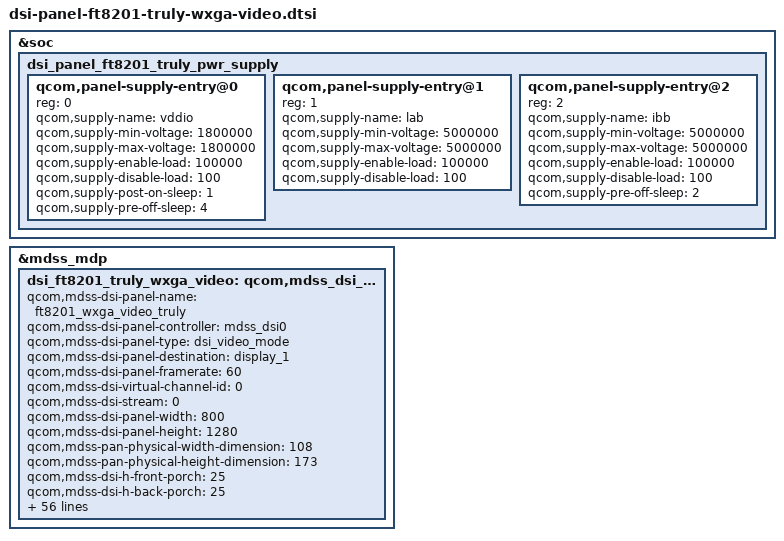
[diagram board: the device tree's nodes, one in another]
/* Copyright (c) 2013, The Linux Foundation. All rights reserved.
 *
 * This program is free software; you can redistribute it and/or modify
 * it under the terms of the GNU General Public License version 2 and
 * only version 2 as published by the Free Software Foundation.
 *
 * This program is distributed in the hope that it will be useful,
 * but WITHOUT ANY WARRANTY; without even the implied warranty of
 * MERCHANTABILITY or FITNESS FOR A PARTICULAR PURPOSE.  See the
 * GNU General Public License for more details.
 */

/*---------------------------------------------------------------------------
 * This file is autogenerated file using gcdb parser. Please do not edit it.
 * Update input XML file to add a new entry or update variable in this file
 * VERSION = "1.0"
 *---------------------------------------------------------------------------*/
&soc {
	dsi_panel_ft8201_truly_pwr_supply: dsi_panel_ft8201_truly_pwr_supply {
		#address-cells = <1>;
		#size-cells = <0>;

		qcom,panel-supply-entry@0 {
			reg = <0>;
			qcom,supply-name = "vddio";
			qcom,supply-min-voltage = <1800000>;
			qcom,supply-max-voltage = <1800000>;
			qcom,supply-enable-load = <100000>;
			qcom,supply-disable-load = <100>;
			qcom,supply-post-on-sleep = <1>;
			qcom,supply-pre-off-sleep = <4>;
		};

		qcom,panel-supply-entry@1 {
			reg = <1>;
			qcom,supply-name = "lab";
			qcom,supply-min-voltage = <5000000>;
			qcom,supply-max-voltage = <5000000>;
			qcom,supply-enable-load = <100000>;
			qcom,supply-disable-load = <100>;
			//qcom,supply-post-off-sleep = <1>;
		};

		qcom,panel-supply-entry@2 {
			reg = <2>;
			qcom,supply-name = "ibb";
			qcom,supply-min-voltage = <5000000>;
			qcom,supply-max-voltage = <5000000>;
			qcom,supply-enable-load = <100000>;
			qcom,supply-disable-load = <100>;
			qcom,supply-pre-off-sleep = <2>;
			//qcom,supply-post-on-sleep = <6>;
		};
	};
};
&mdss_mdp {
	dsi_ft8201_truly_wxga_video: qcom,mdss_dsi_ft8201_truly_wxga_video {
		qcom,mdss-dsi-panel-name = "ft8201_wxga_video_truly";
		qcom,mdss-dsi-panel-controller = <&mdss_dsi0>;
		qcom,mdss-dsi-panel-type = "dsi_video_mode";
		qcom,mdss-dsi-panel-destination = "display_1";
		qcom,mdss-dsi-panel-framerate = <60>;
		qcom,mdss-dsi-virtual-channel-id = <0>;
		qcom,mdss-dsi-stream = <0>;
		qcom,mdss-dsi-panel-width = <800>;
		qcom,mdss-dsi-panel-height = <1280>;
		qcom,mdss-pan-physical-width-dimension = <108>;
		qcom,mdss-pan-physical-height-dimension = <173>;
		qcom,mdss-dsi-h-front-porch = <25>;
		qcom,mdss-dsi-h-back-porch = <25>;
		qcom,mdss-dsi-h-pulse-width = <14>;
		qcom,mdss-dsi-h-sync-skew = <0>;
		qcom,mdss-dsi-v-back-porch = <32>;
		qcom,mdss-dsi-v-front-porch = <146>;
		qcom,mdss-dsi-v-pulse-width = <8>;
		qcom,mdss-dsi-h-left-border = <0>;
		qcom,mdss-dsi-h-right-border = <0>;
		qcom,mdss-dsi-v-top-border = <0>;
		qcom,mdss-dsi-v-bottom-border = <0>;
		qcom,mdss-dsi-bpp = <24>;
		qcom,mdss-dsi-color-order = "rgb_swap_rgb";
		qcom,mdss-dsi-underflow-color = <0xff>;
		qcom,mdss-dsi-border-color = <0>;
		qcom,mdss-dsi-on-command = [
					05 01 00 00 78 00 02 11 00
					05 01 00 00 14 00 02 29 00];
		qcom,mdss-dsi-off-command = [05 01 00 00 14 00 02 28 00
					05 01 00 00 78 00 02 10 00];
		qcom,mdss-dsi-on-command-state = "dsi_lp_mode";
		qcom,mdss-dsi-off-command-state = "dsi_lp_mode";
		qcom,mdss-dsi-h-sync-pulse = <1>;
		qcom,mdss-dsi-traffic-mode = "burst_mode";
		qcom,mdss-dsi-lane-map = "lane_map_0123";
		qcom,mdss-dsi-bllp-eof-power-mode;
		qcom,mdss-dsi-bllp-power-mode;
		qcom,mdss-dsi-lane-0-state;
		qcom,mdss-dsi-lane-1-state;
		qcom,mdss-dsi-lane-2-state;
		qcom,mdss-dsi-lane-3-state;
		qcom,mdss-dsi-panel-timings-phy-12nm = [09 06 0A 02 00 05 02 08];
		//qcom,mdss-dsi-t-clk-post = <0x04>;
		//qcom,mdss-dsi-t-clk-pre = <0x1A>;
		qcom,mdss-dsi-dma-trigger = "trigger_sw";
		qcom,mdss-dsi-mdp-trigger = "none";
		qcom,mdss-dsi-bl-min-level = <1>;
		qcom,mdss-dsi-bl-max-level = <255>;
		qcom,mdss-dsi-bl-pmic-control-type = "bl_ctrl_pwm";
		qcom,mdss-dsi-bl-pmic-pwm-frequency = <50>;
		qcom,mdss-dsi-bl-pmic-bank-select = <0>;
		qcom,mdss-dsi-pwm-gpio = <&pm8953_gpios 8 0>;
		ss,blmap-size = <256>;
		ss,blmap = < 0 2 2 2 2 2 2 2 2 2
					2 2 3 3 4 5 6 7 8 9
					10 11 12 13 14 15 16 17 18 19
					20 21 22 23 24 25 26 27 28 29
					30 31 32 33 34 35 36 37 38 39
					40 41 42 43 44 45 46 47 48 49
					50 51 52 53 54 55 56 57 58 59
					60 61 62 63 64 65 66 67 68 69
					70 71 72 73 74 75 76 77 78 79
					80 81 82 83 84 85 86 87 88 89
					90 91 92 93 94 95 96 97 98 99
					100 101 102 103 104 105 106 107 108 109
					110 111 112 113 114 115 116 117 118 119
					120 121 122 123 124 125 126 127 128 129
					130 131 132 133 134 135 136 137 138 139
					140 141 142 143 144 145 146 147 148 149
					150 151 152 153 154 155 156 157 158 159
					160 161 162 163 164 165 166 167 168 169
					170 171 172 173 174 175 176 177 178 179
					180 181 182 183 184 185 186 187 188 189
					190 191 192 193 194 195 196 197 198 199
					200 201 202 203 204 205 206 207 208 209
					210 211 212 213 214 215 216 217 218 219
					220 221 222 223 224 225 226 227 228 229
					230 231 232 233 234 236 238 240 242 244
					246 248 250 252 254 255>;

		qcom,mdss-dsi-lp11-init;
		qcom,mdss-dsi-init-delay-us = <1000>;
		qcom,mdss-dsi-reset-sequence = <1 1>, <0 10>, <1 120>;
		//qcom,esd-check-enabled;
		qcom,mdss-dsi-panel-status-command = [06 01 00 01 05 00 02 0A 08];
		qcom,mdss-dsi-panel-status-command-state = "dsi_lp_mode";
		qcom,mdss-dsi-panel-status-check-mode = "reg_read";
		qcom,mdss-dsi-panel-status-valid-params = <1>;
		qcom,mdss-dsi-panel-status-value = <0x9C>;
		qcom,mdss-dsi-panel-status-read-length = <1>;
		qcom,panel-supply-entries = <&dsi_panel_ft8201_truly_pwr_supply>;
	};
};
